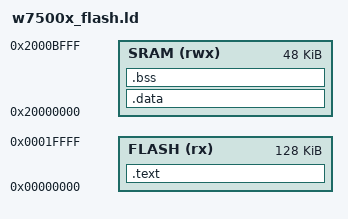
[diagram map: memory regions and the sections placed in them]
/* W7500P Linker Script — 128KB Flash, 48KB SRAM */

MEMORY
{
    FLASH (rx)  : ORIGIN = 0x00000000, LENGTH = 128K
    SRAM  (rwx) : ORIGIN = 0x20000000, LENGTH = 48K
}

/* Reserve last 1KB of flash for config storage */
_config_start = 0x0001FC00;

ENTRY(Reset_Handler)

SECTIONS
{
    .text :
    {
        KEEP(*(.isr_vector))
        *(.text*)
        *(.rodata*)
        . = ALIGN(4);
        _etext = .;
    } > FLASH

    .data : AT(_etext)
    {
        _sdata = .;
        *(.data*)
        . = ALIGN(4);
        _edata = .;
    } > SRAM

    .bss :
    {
        _sbss = .;
        *(.bss*)
        *(COMMON)
        . = ALIGN(4);
        _ebss = .;
    } > SRAM

    _estack = ORIGIN(SRAM) + LENGTH(SRAM);
}
